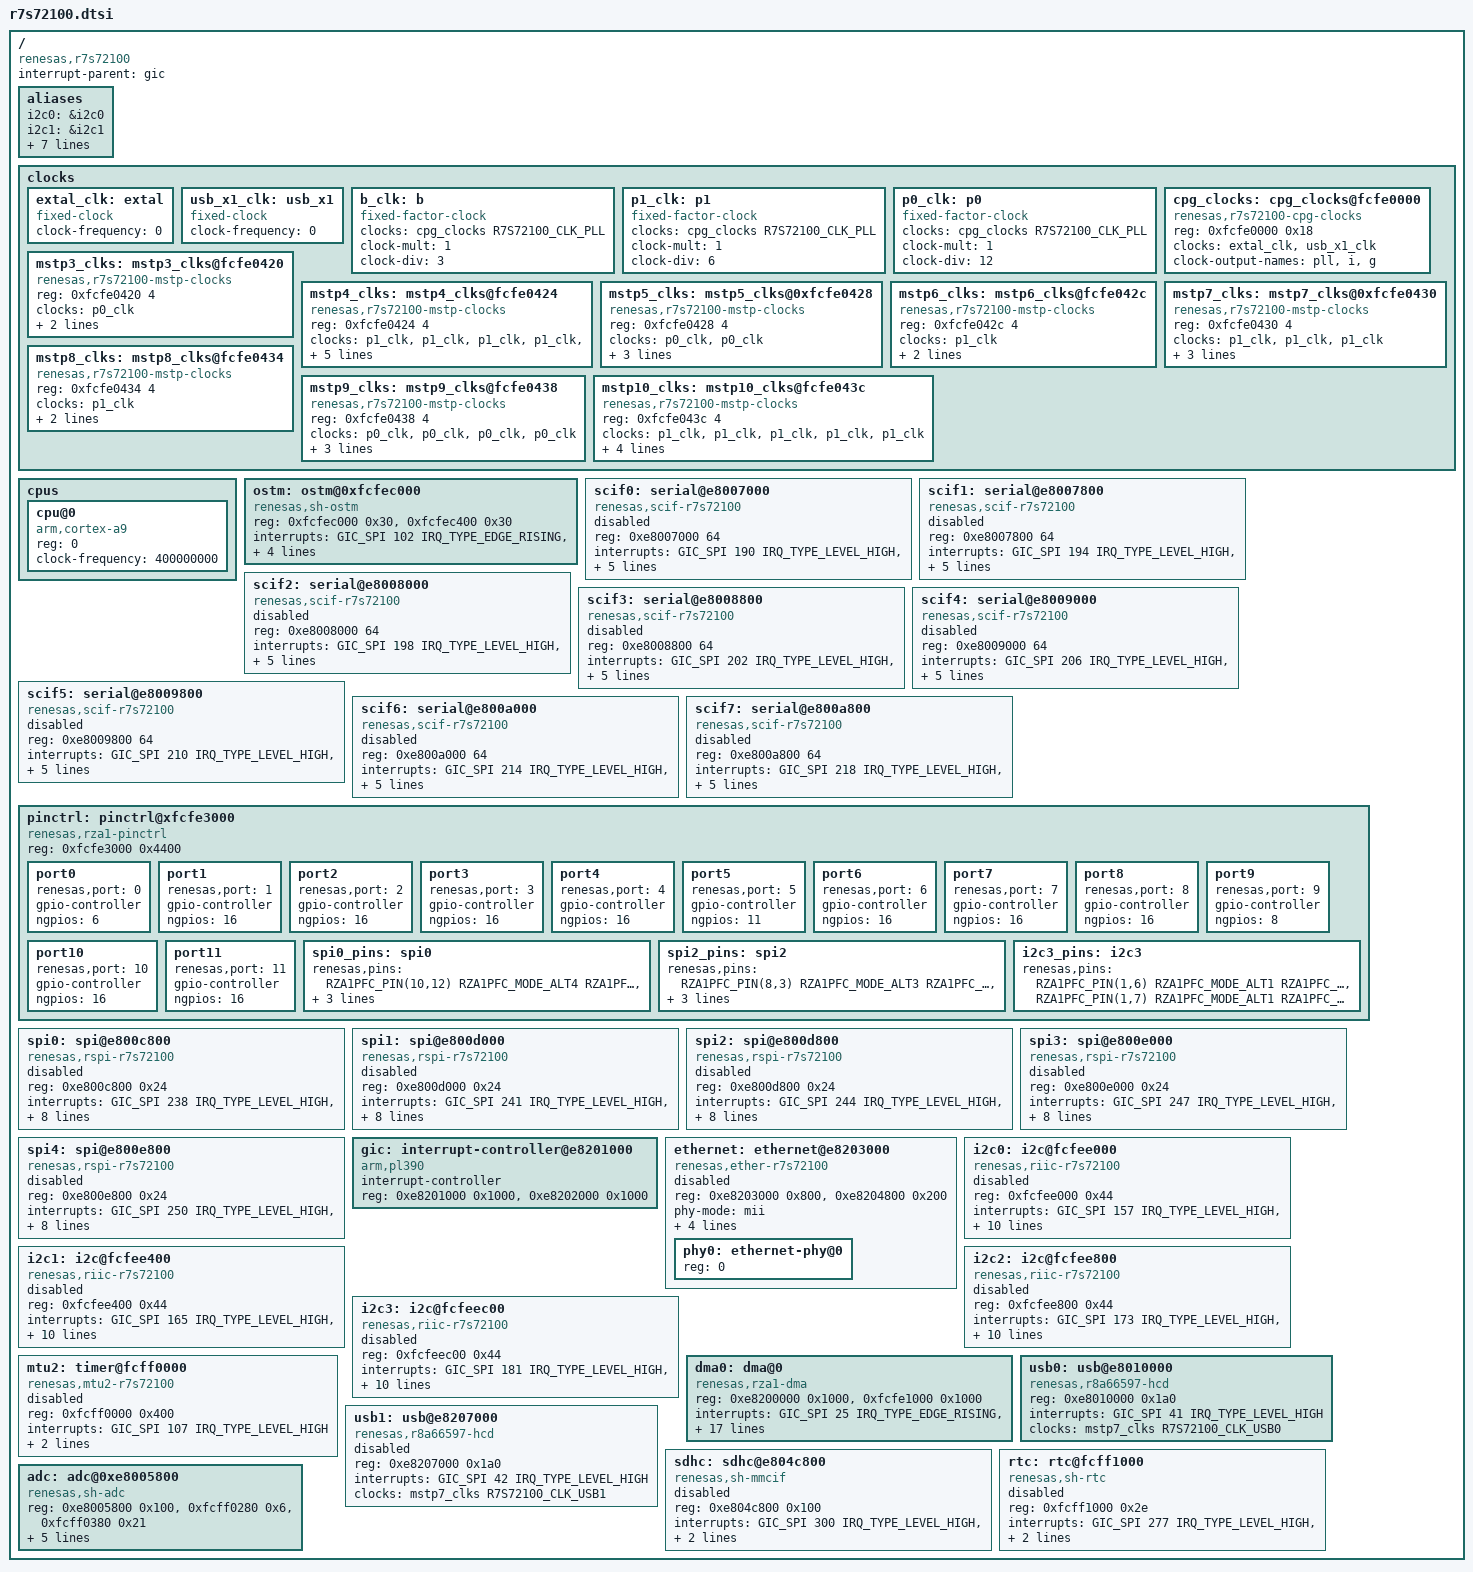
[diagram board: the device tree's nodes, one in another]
/*
 * Device Tree Source for the r7s72100 SoC
 *
 * Copyright (C) 2013-14 Renesas Solutions Corp.
 * Copyright (C) 2014 Wolfram Sang, Sang Engineering <wsa@sang-engineering.com>
 *
 * This file is licensed under the terms of the GNU General Public License
 * version 2.  This program is licensed "as is" without any warranty of any
 * kind, whether express or implied.
 */

#include <dt-bindings/pinctrl/rza1pfc.h>
#include <dt-bindings/dma/rza1dma.h>
#include <dt-bindings/clock/r7s72100-clock.h>
#include <dt-bindings/interrupt-controller/arm-gic.h>
#include <dt-bindings/interrupt-controller/irq.h>

/ {
	compatible = "renesas,r7s72100";
	interrupt-parent = <&gic>;
	#address-cells = <1>;
	#size-cells = <1>;

	aliases {
		i2c0 = &i2c0;
		i2c1 = &i2c1;
		i2c2 = &i2c2;
		i2c3 = &i2c3;
		spi0 = &spi0;
		spi1 = &spi1;
		spi2 = &spi2;
		spi3 = &spi3;
		spi4 = &spi4;
	};

	clocks {
		ranges;
		#address-cells = <1>;
		#size-cells = <1>;

		/* External clocks */
		extal_clk: extal {
			#clock-cells = <0>;
			compatible = "fixed-clock";
			/* If clk present, value must be set by board */
			clock-frequency = <0>;
		};

		usb_x1_clk: usb_x1 {
			#clock-cells = <0>;
			compatible = "fixed-clock";
			/* If clk present, value must be set by board */
			clock-frequency = <0>;
		};

		/* Fixed factor clocks */
		b_clk: b {
			#clock-cells = <0>;
			compatible = "fixed-factor-clock";
			clocks = <&cpg_clocks R7S72100_CLK_PLL>;
			clock-mult = <1>;
			clock-div = <3>;
		};
		p1_clk: p1 {
			#clock-cells = <0>;
			compatible = "fixed-factor-clock";
			clocks = <&cpg_clocks R7S72100_CLK_PLL>;
			clock-mult = <1>;
			clock-div = <6>;
		};
		p0_clk: p0 {
			#clock-cells = <0>;
			compatible = "fixed-factor-clock";
			clocks = <&cpg_clocks R7S72100_CLK_PLL>;
			clock-mult = <1>;
			clock-div = <12>;
		};

		/* Special CPG clocks */
		cpg_clocks: cpg_clocks@fcfe0000 {
			#clock-cells = <1>;
			compatible = "renesas,r7s72100-cpg-clocks",
				     "renesas,rz-cpg-clocks";
			reg = <0xfcfe0000 0x18>;
			clocks = <&extal_clk>, <&usb_x1_clk>;
			clock-output-names = "pll", "i", "g";
			#power-domain-cells = <0>;
		};

		/* MSTP clocks */
		mstp3_clks: mstp3_clks@fcfe0420 {
			#clock-cells = <1>;
			compatible = "renesas,r7s72100-mstp-clocks", "renesas,cpg-mstp-clocks";
			reg = <0xfcfe0420 4>;
			clocks = <&p0_clk>;
			clock-indices = <R7S72100_CLK_MTU2>;
			clock-output-names = "mtu2";
		};

		mstp4_clks: mstp4_clks@fcfe0424 {
			#clock-cells = <1>;
			compatible = "renesas,r7s72100-mstp-clocks", "renesas,cpg-mstp-clocks";
			reg = <0xfcfe0424 4>;
			clocks = <&p1_clk>, <&p1_clk>, <&p1_clk>, <&p1_clk>,
				 <&p1_clk>, <&p1_clk>, <&p1_clk>, <&p1_clk>;
			clock-indices = <
				R7S72100_CLK_SCIF0 R7S72100_CLK_SCIF1 R7S72100_CLK_SCIF2 R7S72100_CLK_SCIF3
				R7S72100_CLK_SCIF4 R7S72100_CLK_SCIF5 R7S72100_CLK_SCIF6 R7S72100_CLK_SCIF7
			>;
			clock-output-names = "scif0", "scif1", "scif2", "scif3", "scif4", "scif5", "scif6", "scif7";
		};
		
		mstp5_clks: mstp5_clks@0xfcfe0428 {
			#clock-cells = <1>;
			compatible = "renesas,r7s72100-mstp-clocks", "renesas,cpg-mstp-clocks";
			reg = <0xfcfe0428 4>;
			clocks = <&p0_clk>, <&p0_clk>;
			clock-indices = <
				R7S72100_CLK_OSTM1 R7S72100_CLK_OSTM0
			>;
			clock-output-names = "ostm1", "ostm0";
		};
		
		mstp6_clks: mstp6_clks@fcfe042c {
			#clock-cells = <1>;
			compatible = "renesas,r7s72100-mstp-clocks", "renesas,cpg-mstp-clocks";
			reg = <0xfcfe042c 4>;
			clocks = <&p1_clk>;
			clock-indices = <
				R7S72100_CLK_ADC
			>;
			clock-output-names = "adc";
		};
		
		mstp7_clks: mstp7_clks@0xfcfe0430 {
			#clock-cells = <1>;
			compatible = "renesas,r7s72100-mstp-clocks", "renesas,cpg-mstp-clocks";
			reg = <0xfcfe0430 4>;
			clocks = <&p1_clk>, <&p1_clk>, <&p1_clk>;
			clock-indices = <
				R7S72100_CLK_USB1 R7S72100_CLK_USB0 R7S72100_CLK_ETHER
			>;
			clock-output-names = "usb1", "usb0", "ether";
		};
		
		mstp8_clks: mstp8_clks@fcfe0434 {
			#clock-cells = <1>;
			compatible = "renesas,r7s72100-mstp-clocks", "renesas,cpg-mstp-clocks";
			reg = <0xfcfe0434 4>;
			clocks = <&p1_clk>;
			clock-indices = <
				R7S72100_CLK_MMC
			>;
			clock-output-names = "mmc";
		};

		mstp9_clks: mstp9_clks@fcfe0438 {
			#clock-cells = <1>;
			compatible = "renesas,r7s72100-mstp-clocks", "renesas,cpg-mstp-clocks";
			reg = <0xfcfe0438 4>;
			clocks = <&p0_clk>, <&p0_clk>, <&p0_clk>, <&p0_clk>;
			clock-indices = <
				R7S72100_CLK_I2C0 R7S72100_CLK_I2C1 R7S72100_CLK_I2C2 R7S72100_CLK_I2C3
			>;
			clock-output-names = "i2c0", "i2c1", "i2c2", "i2c3";
		};

		mstp10_clks: mstp10_clks@fcfe043c {
			#clock-cells = <1>;
			compatible = "renesas,r7s72100-mstp-clocks", "renesas,cpg-mstp-clocks";
			reg = <0xfcfe043c 4>;
			clocks = <&p1_clk>, <&p1_clk>, <&p1_clk>, <&p1_clk>,
				 <&p1_clk>;
			clock-indices = <
				R7S72100_CLK_SPI0 R7S72100_CLK_SPI1 R7S72100_CLK_SPI2 R7S72100_CLK_SPI3
				R7S72100_CLK_SPI4
			>;
			clock-output-names = "spi0", "spi1", "spi2", "spi3", "spi4";
		};
		
	};

	cpus {
		#address-cells = <1>;
		#size-cells = <0>;

		cpu@0 {
			device_type = "cpu";
			compatible = "arm,cortex-a9";
			reg = <0>;
			clock-frequency = <400000000>;
		};
	};
	
	ostm: ostm@0xfcfec000 {
		compatible = "renesas,sh-ostm";
		reg = <0xfcfec000 0x30>, <0xfcfec400 0x30>;
		interrupts = <GIC_SPI 102 IRQ_TYPE_EDGE_RISING>, <GIC_SPI 103 IRQ_TYPE_EDGE_RISING>;
		clocks = <&mstp5_clks R7S72100_CLK_OSTM1>, <&mstp5_clks R7S72100_CLK_OSTM0>;
		status = "okay";
		renesas,clkratings = <300 300>;
	};

	scif0: serial@e8007000 {
		compatible = "renesas,scif-r7s72100", "renesas,scif";
		reg = <0xe8007000 64>;
		interrupts = <GIC_SPI 190 IRQ_TYPE_LEVEL_HIGH>,
			     <GIC_SPI 191 IRQ_TYPE_LEVEL_HIGH>,
			     <GIC_SPI 192 IRQ_TYPE_LEVEL_HIGH>,
			     <GIC_SPI 189 IRQ_TYPE_LEVEL_HIGH>;
		clocks = <&mstp4_clks R7S72100_CLK_SCIF0>;
		clock-names = "fck";
		power-domains = <&cpg_clocks>;
		status = "disabled";
	};

	scif1: serial@e8007800 {
		compatible = "renesas,scif-r7s72100", "renesas,scif";
		reg = <0xe8007800 64>;
		interrupts = <GIC_SPI 194 IRQ_TYPE_LEVEL_HIGH>,
			     <GIC_SPI 195 IRQ_TYPE_LEVEL_HIGH>,
			     <GIC_SPI 196 IRQ_TYPE_LEVEL_HIGH>,
			     <GIC_SPI 193 IRQ_TYPE_LEVEL_HIGH>;
		clocks = <&mstp4_clks R7S72100_CLK_SCIF1>;
		clock-names = "fck";
		power-domains = <&cpg_clocks>;
		status = "disabled";
	};

	scif2: serial@e8008000 {
		compatible = "renesas,scif-r7s72100", "renesas,scif";
		reg = <0xe8008000 64>;
		interrupts = <GIC_SPI 198 IRQ_TYPE_LEVEL_HIGH>,
			     <GIC_SPI 199 IRQ_TYPE_LEVEL_HIGH>,
			     <GIC_SPI 200 IRQ_TYPE_LEVEL_HIGH>,
			     <GIC_SPI 197 IRQ_TYPE_LEVEL_HIGH>;
		clocks = <&mstp4_clks R7S72100_CLK_SCIF2>;
		clock-names = "fck";
		power-domains = <&cpg_clocks>;
		status = "disabled";
	};

	scif3: serial@e8008800 {
		compatible = "renesas,scif-r7s72100", "renesas,scif";
		reg = <0xe8008800 64>;
		interrupts = <GIC_SPI 202 IRQ_TYPE_LEVEL_HIGH>,
			     <GIC_SPI 203 IRQ_TYPE_LEVEL_HIGH>,
			     <GIC_SPI 204 IRQ_TYPE_LEVEL_HIGH>,
			     <GIC_SPI 201 IRQ_TYPE_LEVEL_HIGH>;
		clocks = <&mstp4_clks R7S72100_CLK_SCIF3>;
		clock-names = "fck";
		power-domains = <&cpg_clocks>;
		status = "disabled";
	};

	scif4: serial@e8009000 {
		compatible = "renesas,scif-r7s72100", "renesas,scif";
		reg = <0xe8009000 64>;
		interrupts = <GIC_SPI 206 IRQ_TYPE_LEVEL_HIGH>,
			     <GIC_SPI 207 IRQ_TYPE_LEVEL_HIGH>,
			     <GIC_SPI 208 IRQ_TYPE_LEVEL_HIGH>,
			     <GIC_SPI 205 IRQ_TYPE_LEVEL_HIGH>;
		clocks = <&mstp4_clks R7S72100_CLK_SCIF4>;
		clock-names = "fck";
		power-domains = <&cpg_clocks>;
		status = "disabled";
	};

	scif5: serial@e8009800 {
		compatible = "renesas,scif-r7s72100", "renesas,scif";
		reg = <0xe8009800 64>;
		interrupts = <GIC_SPI 210 IRQ_TYPE_LEVEL_HIGH>,
			     <GIC_SPI 211 IRQ_TYPE_LEVEL_HIGH>,
			     <GIC_SPI 212 IRQ_TYPE_LEVEL_HIGH>,
			     <GIC_SPI 209 IRQ_TYPE_LEVEL_HIGH>;
		clocks = <&mstp4_clks R7S72100_CLK_SCIF5>;
		clock-names = "fck";
		power-domains = <&cpg_clocks>;
		status = "disabled";
	};

	scif6: serial@e800a000 {
		compatible = "renesas,scif-r7s72100", "renesas,scif";
		reg = <0xe800a000 64>;
		interrupts = <GIC_SPI 214 IRQ_TYPE_LEVEL_HIGH>,
			     <GIC_SPI 215 IRQ_TYPE_LEVEL_HIGH>,
			     <GIC_SPI 216 IRQ_TYPE_LEVEL_HIGH>,
			     <GIC_SPI 213 IRQ_TYPE_LEVEL_HIGH>;
		clocks = <&mstp4_clks R7S72100_CLK_SCIF6>;
		clock-names = "fck";
		power-domains = <&cpg_clocks>;
		status = "disabled";
	};

	scif7: serial@e800a800 {
		compatible = "renesas,scif-r7s72100", "renesas,scif";
		reg = <0xe800a800 64>;
		interrupts = <GIC_SPI 218 IRQ_TYPE_LEVEL_HIGH>,
			     <GIC_SPI 219 IRQ_TYPE_LEVEL_HIGH>,
			     <GIC_SPI 220 IRQ_TYPE_LEVEL_HIGH>,
			     <GIC_SPI 217 IRQ_TYPE_LEVEL_HIGH>;
		clocks = <&mstp4_clks R7S72100_CLK_SCIF7>;
		clock-names = "fck";
		power-domains = <&cpg_clocks>;
		status = "disabled";
	};
	
	pinctrl: pinctrl@xfcfe3000 {
		compatible = "renesas,rza1-pinctrl";
		reg = <0xfcfe3000 0x4400>;
		
		port0: port0 {
			renesas,port = <0>;
			gpio-controller;
			#gpio-cells = <2>;
			ngpios = <6>;
		};
		
		port1: port1 {
			renesas,port = <1>;
			gpio-controller;
			#gpio-cells = <2>;
			ngpios = <16>;
		};
		
		port2: port2 {
			renesas,port = <2>;
			gpio-controller;
			#gpio-cells = <2>;
			ngpios = <16>;
		};
		
		port3: port3 {
			renesas,port = <3>;
			gpio-controller;
			#gpio-cells = <2>;
			ngpios = <16>;
		};
		
		port4: port4 {
			renesas,port = <4>;
			gpio-controller;
			#gpio-cells = <2>;
			ngpios = <16>;
		};
		
		port5: port5 {
			renesas,port = <5>;
			gpio-controller;
			#gpio-cells = <2>;
			ngpios = <11>;
		};
		
		port6: port6 {
			renesas,port = <6>;
			gpio-controller;
			#gpio-cells = <2>;
			ngpios = <16>;
		};
		
		port7: port7 {
			renesas,port = <7>;
			gpio-controller;
			#gpio-cells = <2>;
			ngpios = <16>;
		};
		
		port8: port8 {
			renesas,port = <8>;
			gpio-controller;
			#gpio-cells = <2>;
			ngpios = <16>;
		};
		
		port9: port9 {
			renesas,port = <9>;
			gpio-controller;
			#gpio-cells = <2>;
			ngpios = <8>;
		};
		
		port10: port10 {
			renesas,port = <10>;
			gpio-controller;
			#gpio-cells = <2>;
			ngpios = <16>;
		};
		
		port11: port11 {
			renesas,port = <11>;
			gpio-controller;
			#gpio-cells = <2>;
			ngpios = <16>;
		};
		
		spi0_pins: spi0 {
			renesas,pins = <RZA1PFC_PIN(10,12) RZA1PFC_MODE_ALT4 RZA1PFC_DIIO_PBDC_EN>,	/* sck */
							<RZA1PFC_PIN(10,13) RZA1PFC_MODE_ALT4 RZA1PFC_DIIO_PBDC_EN>,/* ssl */
							<RZA1PFC_PIN(10,14) RZA1PFC_MODE_ALT4 RZA1PFC_DIIO_PBDC_EN>,/* mosi */
							<RZA1PFC_PIN(10,15) RZA1PFC_MODE_ALT4 RZA1PFC_DIIO_PBDC_EN>;/* miso */
							
							
		};
		
		spi2_pins: spi2 {
			renesas,pins = <RZA1PFC_PIN(8,3) RZA1PFC_MODE_ALT3 RZA1PFC_DIIO_PBDC_EN>,	/* sck */
							<RZA1PFC_PIN(8,4) RZA1PFC_MODE_ALT3 RZA1PFC_DIIO_PBDC_EN>,	/* ssl */
							<RZA1PFC_PIN(8,5) RZA1PFC_MODE_ALT3 RZA1PFC_DIIO_PBDC_EN>,	/* mosi */
							<RZA1PFC_PIN(8,6) RZA1PFC_MODE_ALT3 RZA1PFC_DIIO_PBDC_EN>;	/* miso */
		};
								
		i2c3_pins: i2c3 {
			renesas,pins = <RZA1PFC_PIN(1,6) RZA1PFC_MODE_ALT1 RZA1PFC_DIIO_PBDC_EN>,	/* scl */
							<RZA1PFC_PIN(1,7) RZA1PFC_MODE_ALT1 RZA1PFC_DIIO_PBDC_EN>;	/* sda */
														
		};
	};
	
	spi0: spi@e800c800 {
		compatible = "renesas,rspi-r7s72100", "renesas,rspi-rz";
		reg = <0xe800c800 0x24>;
		interrupts = <GIC_SPI 238 IRQ_TYPE_LEVEL_HIGH>,
			     <GIC_SPI 239 IRQ_TYPE_LEVEL_HIGH>,
			     <GIC_SPI 240 IRQ_TYPE_LEVEL_HIGH>;
		interrupt-names = "error", "rx", "tx";
		clocks = <&mstp10_clks R7S72100_CLK_SPI0>;
		power-domains = <&cpg_clocks>;
		num-cs = <1>;
		#address-cells = <1>;
		#size-cells = <0>;
		dmas = <&dma0
					0xe800C804 
					RZA1DMA_DMARS(0x1, RZA1DMA_SPI0) 
					RZA1DMA_CHCFGM(RZA1DMA_REQD_DESTINATION, 0x0, 0x1, 0x1, RZA1DMA_AMA_BUSCYCLEMODE, RZA1DMA_CHCFG_64BIT, RZA1DMA_CHCFG_8BIT, 0x0)
					0>,
				<&dma0 
					0xe800C804 
					RZA1DMA_DMARS(0x2, RZA1DMA_SPI0)
					RZA1DMA_CHCFGM(RZA1DMA_REQD_SOURCE, 0x0, 0x1, 0x1, RZA1DMA_AMA_BUSCYCLEMODE, RZA1DMA_CHCFG_8BIT, RZA1DMA_CHCFG_8BIT, 0x0)
					0>;
		dma-names = "tx", "rx";
		status = "disabled";
	};

	spi1: spi@e800d000 {
		compatible = "renesas,rspi-r7s72100", "renesas,rspi-rz";
		reg = <0xe800d000 0x24>;
		interrupts = <GIC_SPI 241 IRQ_TYPE_LEVEL_HIGH>,
			     <GIC_SPI 242 IRQ_TYPE_LEVEL_HIGH>,
			     <GIC_SPI 243 IRQ_TYPE_LEVEL_HIGH>;
		interrupt-names = "error", "rx", "tx";
		clocks = <&mstp10_clks R7S72100_CLK_SPI1>;
		power-domains = <&cpg_clocks>;
		num-cs = <1>;
		#address-cells = <1>;
		#size-cells = <0>;
		dmas = <&dma0 
					0xe800D004 
					RZA1DMA_DMARS(0x1, RZA1DMA_SPI1) 
					RZA1DMA_CHCFGM(RZA1DMA_REQD_DESTINATION, 0x0, 0x1, 0x1, RZA1DMA_AMA_BUSCYCLEMODE, RZA1DMA_CHCFG_8BIT, RZA1DMA_CHCFG_8BIT, 0x0)
					0>,
				<&dma0 
					0xe800D004 
					RZA1DMA_DMARS(0x2, RZA1DMA_SPI1)
					RZA1DMA_CHCFGM(RZA1DMA_REQD_SOURCE, 0x0, 0x1, 0x1, RZA1DMA_AMA_BUSCYCLEMODE, RZA1DMA_CHCFG_8BIT, RZA1DMA_CHCFG_8BIT, 0x0)
					0>;
		dma-names = "tx", "rx";
		status = "disabled";
	};

	spi2: spi@e800d800 {
		compatible = "renesas,rspi-r7s72100", "renesas,rspi-rz";
		reg = <0xe800d800 0x24>;
		interrupts = <GIC_SPI 244 IRQ_TYPE_LEVEL_HIGH>,
			     <GIC_SPI 245 IRQ_TYPE_LEVEL_HIGH>,
			     <GIC_SPI 246 IRQ_TYPE_LEVEL_HIGH>;
		interrupt-names = "error", "rx", "tx";
		clocks = <&mstp10_clks R7S72100_CLK_SPI2>;
		power-domains = <&cpg_clocks>;
		num-cs = <1>;
		#address-cells = <1>;
		#size-cells = <0>;
		dmas =	<&dma0 
					0xe800D804
					RZA1DMA_DMARS(0x1, RZA1DMA_SPI2)
					RZA1DMA_CHCFGM(RZA1DMA_REQD_DESTINATION, 0x0, 0x1, 0x1, RZA1DMA_AMA_BUSCYCLEMODE, RZA1DMA_CHCFG_64BIT, RZA1DMA_CHCFG_8BIT, 0x0)
					0>,
				<&dma0
					0xe800D804 
					RZA1DMA_DMARS(0x2, RZA1DMA_SPI2)
					RZA1DMA_CHCFGM(RZA1DMA_REQD_SOURCE, 0x0, 0x1, 0x1, RZA1DMA_AMA_BUSCYCLEMODE, RZA1DMA_CHCFG_8BIT, RZA1DMA_CHCFG_8BIT, 0x0)
					0>;
		dma-names = "tx", "rx";
		status = "disabled";
	};

	spi3: spi@e800e000 {
		compatible = "renesas,rspi-r7s72100", "renesas,rspi-rz";
		reg = <0xe800e000 0x24>;
		interrupts = <GIC_SPI 247 IRQ_TYPE_LEVEL_HIGH>,
			     <GIC_SPI 248 IRQ_TYPE_LEVEL_HIGH>,
			     <GIC_SPI 249 IRQ_TYPE_LEVEL_HIGH>;
		interrupt-names = "error", "rx", "tx";
		clocks = <&mstp10_clks R7S72100_CLK_SPI3>;
		power-domains = <&cpg_clocks>;
		num-cs = <1>;
		#address-cells = <1>;
		#size-cells = <0>;
		dmas = <&dma0 
					0xe800E004
					RZA1DMA_DMARS(0x1, RZA1DMA_SPI3)
					RZA1DMA_CHCFGM(RZA1DMA_REQD_DESTINATION, 0x0, 0x1, 0x1, RZA1DMA_AMA_BUSCYCLEMODE, RZA1DMA_CHCFG_8BIT, RZA1DMA_CHCFG_8BIT, 0x0)
					0>,
				<&dma0
					0xe800E004
					RZA1DMA_DMARS(0x2, RZA1DMA_SPI3)
					RZA1DMA_CHCFGM(RZA1DMA_REQD_SOURCE, 0x0, 0x1, 0x1, RZA1DMA_AMA_BUSCYCLEMODE, RZA1DMA_CHCFG_8BIT, RZA1DMA_CHCFG_8BIT, 0x0)
					0>;
		dma-names = "tx", "rx";
		status = "disabled";
	};

	spi4: spi@e800e800 {
		compatible = "renesas,rspi-r7s72100", "renesas,rspi-rz";
		reg = <0xe800e800 0x24>;
		interrupts = <GIC_SPI 250 IRQ_TYPE_LEVEL_HIGH>,
			     <GIC_SPI 251 IRQ_TYPE_LEVEL_HIGH>,
			     <GIC_SPI 252 IRQ_TYPE_LEVEL_HIGH>;
		interrupt-names = "error", "rx", "tx";
		clocks = <&mstp10_clks R7S72100_CLK_SPI4>;
		power-domains = <&cpg_clocks>;
		num-cs = <1>;
		#address-cells = <1>;
		#size-cells = <0>;
		dmas = <&dma0 
					0xe800E804
					RZA1DMA_DMARS(0x1, RZA1DMA_SPI4)
					RZA1DMA_CHCFGM(RZA1DMA_REQD_DESTINATION, 0x0, 0x1, 0x1, RZA1DMA_AMA_BUSCYCLEMODE, RZA1DMA_CHCFG_8BIT, RZA1DMA_CHCFG_8BIT, 0x0)
					0>,
				<&dma0
					0xe800E804
					RZA1DMA_DMARS(0x2, RZA1DMA_SPI4)
					RZA1DMA_CHCFGM(RZA1DMA_REQD_SOURCE, 0x0, 0x1, 0x1, RZA1DMA_AMA_BUSCYCLEMODE, RZA1DMA_CHCFG_8BIT, RZA1DMA_CHCFG_8BIT, 0x0)
					0>;
		dma-names = "tx", "rx";
		status = "disabled";
	};

	gic: interrupt-controller@e8201000 {
		compatible = "arm,pl390";
		#interrupt-cells = <3>;
		#address-cells = <0>;
		interrupt-controller;
		reg = <0xe8201000 0x1000>,
			<0xe8202000 0x1000>;
	};

	ethernet: ethernet@e8203000 {
		compatible = "renesas,ether-r7s72100";
		reg = <0xe8203000 0x800>,
			<0xe8204800 0x200>;
		phy-mode = "mii";
		renesas,ether-link-active-low;
    	interrupts = <GIC_SPI 327 IRQ_TYPE_LEVEL_HIGH>;
    	clocks = <&mstp7_clks R7S72100_CLK_ETHER>;
    	phy-handle = <&phy0>;
    	#address-cells = <1>;
		#size-cells = <0>;
		status = "disabled";
		phy0: ethernet-phy@0 {
			reg = <0>;
		};		
	};



	i2c0: i2c@fcfee000 {
		#address-cells = <1>;
		#size-cells = <0>;
		compatible = "renesas,riic-r7s72100", "renesas,riic-rz";
		reg = <0xfcfee000 0x44>;
		interrupts = <GIC_SPI 157 IRQ_TYPE_LEVEL_HIGH>,
			     <GIC_SPI 158 IRQ_TYPE_EDGE_RISING>,
			     <GIC_SPI 159 IRQ_TYPE_EDGE_RISING>,
			     <GIC_SPI 160 IRQ_TYPE_LEVEL_HIGH>,
			     <GIC_SPI 161 IRQ_TYPE_LEVEL_HIGH>,
			     <GIC_SPI 162 IRQ_TYPE_LEVEL_HIGH>,
			     <GIC_SPI 163 IRQ_TYPE_LEVEL_HIGH>,
			     <GIC_SPI 164 IRQ_TYPE_LEVEL_HIGH>;
		clocks = <&mstp9_clks R7S72100_CLK_I2C0>;
		clock-frequency = <100000>;
		power-domains = <&cpg_clocks>;
		status = "disabled";
	};

	i2c1: i2c@fcfee400 {
		#address-cells = <1>;
		#size-cells = <0>;
		compatible = "renesas,riic-r7s72100", "renesas,riic-rz";
		reg = <0xfcfee400 0x44>;
		interrupts = <GIC_SPI 165 IRQ_TYPE_LEVEL_HIGH>,
			     <GIC_SPI 166 IRQ_TYPE_EDGE_RISING>,
			     <GIC_SPI 167 IRQ_TYPE_EDGE_RISING>,
			     <GIC_SPI 168 IRQ_TYPE_LEVEL_HIGH>,
			     <GIC_SPI 169 IRQ_TYPE_LEVEL_HIGH>,
			     <GIC_SPI 170 IRQ_TYPE_LEVEL_HIGH>,
			     <GIC_SPI 171 IRQ_TYPE_LEVEL_HIGH>,
			     <GIC_SPI 172 IRQ_TYPE_LEVEL_HIGH>;
		clocks = <&mstp9_clks R7S72100_CLK_I2C1>;
		clock-frequency = <100000>;
		power-domains = <&cpg_clocks>;
		status = "disabled";
	};

	i2c2: i2c@fcfee800 {
		#address-cells = <1>;
		#size-cells = <0>;
		compatible = "renesas,riic-r7s72100", "renesas,riic-rz";
		reg = <0xfcfee800 0x44>;
		interrupts = <GIC_SPI 173 IRQ_TYPE_LEVEL_HIGH>,
			     <GIC_SPI 174 IRQ_TYPE_EDGE_RISING>,
			     <GIC_SPI 175 IRQ_TYPE_EDGE_RISING>,
			     <GIC_SPI 176 IRQ_TYPE_LEVEL_HIGH>,
			     <GIC_SPI 177 IRQ_TYPE_LEVEL_HIGH>,
			     <GIC_SPI 178 IRQ_TYPE_LEVEL_HIGH>,
			     <GIC_SPI 179 IRQ_TYPE_LEVEL_HIGH>,
			     <GIC_SPI 180 IRQ_TYPE_LEVEL_HIGH>;
		clocks = <&mstp9_clks R7S72100_CLK_I2C2>;
		clock-frequency = <100000>;
		power-domains = <&cpg_clocks>;
		status = "disabled";
	};

	i2c3: i2c@fcfeec00 {
		#address-cells = <1>;
		#size-cells = <0>;
		compatible = "renesas,riic-r7s72100", "renesas,riic-rz";
		reg = <0xfcfeec00 0x44>;
		interrupts = <GIC_SPI 181 IRQ_TYPE_LEVEL_HIGH>,
			     <GIC_SPI 182 IRQ_TYPE_EDGE_RISING>,
			     <GIC_SPI 183 IRQ_TYPE_EDGE_RISING>,
			     <GIC_SPI 184 IRQ_TYPE_LEVEL_HIGH>,
			     <GIC_SPI 185 IRQ_TYPE_LEVEL_HIGH>,
			     <GIC_SPI 186 IRQ_TYPE_LEVEL_HIGH>,
			     <GIC_SPI 187 IRQ_TYPE_LEVEL_HIGH>,
			     <GIC_SPI 188 IRQ_TYPE_LEVEL_HIGH>;
		clocks = <&mstp9_clks R7S72100_CLK_I2C3>;
		clock-frequency = <100000>;
		power-domains = <&cpg_clocks>;
		status = "disabled";
	};

	mtu2: timer@fcff0000 {
		compatible = "renesas,mtu2-r7s72100", "renesas,mtu2";
		reg = <0xfcff0000 0x400>;
		interrupts = <GIC_SPI 107 IRQ_TYPE_LEVEL_HIGH>;
		interrupt-names = "tgi0a";
		clocks = <&mstp3_clks R7S72100_CLK_MTU2>;
		clock-names = "fck";
		power-domains = <&cpg_clocks>;
		status = "disabled";
	};
	
	dma0: dma@0 {
		compatible = "renesas,rza1-dma";
		reg = <0xe8200000 0x1000>,
		 <0xfcfe1000 0x1000>;
		 interrupts =
		 		<GIC_SPI 25 IRQ_TYPE_EDGE_RISING>,	/* error */
		 		<GIC_SPI 9 IRQ_TYPE_EDGE_RISING>,	/* chan0 */
		 		<GIC_SPI 10 IRQ_TYPE_EDGE_RISING>,	/* chan1 */
				<GIC_SPI 11 IRQ_TYPE_EDGE_RISING>,	/* chan2 */
				<GIC_SPI 12 IRQ_TYPE_EDGE_RISING>,	/* chan3 */
				<GIC_SPI 13 IRQ_TYPE_EDGE_RISING>,	/* chan4 */
				<GIC_SPI 14 IRQ_TYPE_EDGE_RISING>,	/* chan5 */
				<GIC_SPI 15 IRQ_TYPE_EDGE_RISING>,	/* chan6 */
				<GIC_SPI 16 IRQ_TYPE_EDGE_RISING>,	/* chan7 */
				<GIC_SPI 17 IRQ_TYPE_EDGE_RISING>,	/* chan8 */
				<GIC_SPI 18 IRQ_TYPE_EDGE_RISING>,	/* chan9 */
				<GIC_SPI 19 IRQ_TYPE_EDGE_RISING>,	/* chan10 */
				<GIC_SPI 20 IRQ_TYPE_EDGE_RISING>,	/* chan11 */
				<GIC_SPI 21 IRQ_TYPE_EDGE_RISING>,	/* chan12 */
				<GIC_SPI 22 IRQ_TYPE_EDGE_RISING>,	/* chan13 */
				<GIC_SPI 23 IRQ_TYPE_EDGE_RISING>,	/* chan14 */
				<GIC_SPI 24 IRQ_TYPE_EDGE_RISING>;	/* chan15 */	
		#dma-cells = <4>; /* registeraddr, dmars, chcfg, interval */
		dma-channels = <16>; /* this can be set to the actual amount of interrupts used to save memory */
	};

	usb0: usb@e8010000 {
		compatible = "renesas,r8a66597-hcd";
		reg = <0xe8010000 0x1a0>;
		interrupts = <GIC_SPI 41 IRQ_TYPE_LEVEL_HIGH>;
		clocks = <&mstp7_clks R7S72100_CLK_USB0>;
		clock-names = "clk";
	};
	
	usb1: usb@e8207000 {
		compatible = "renesas,r8a66597-hcd";
		reg = <0xe8207000 0x1a0>;
		interrupts = <GIC_SPI 42 IRQ_TYPE_LEVEL_HIGH>;
		clocks = <&mstp7_clks R7S72100_CLK_USB1>;
		clock-names = "usb-1";
		status = "disabled";
	};
			
	sdhc: sdhc@e804c800 {
		compatible = "renesas,sh-mmcif";
		reg = <0xe804c800 0x100>;
		interrupts = <GIC_SPI 300 IRQ_TYPE_LEVEL_HIGH>,
		<GIC_SPI 301 IRQ_TYPE_LEVEL_HIGH>;
		clocks = <&mstp8_clks R7S72100_CLK_MMC>;
		status = "disabled";
	};
	
	rtc: rtc@fcff1000 {
		compatible = "renesas,sh-rtc";
		reg = <0xfcff1000 0x2e>;
		interrupts = <GIC_SPI 277 IRQ_TYPE_LEVEL_HIGH>,
			<GIC_SPI 278 IRQ_TYPE_LEVEL_HIGH>,
			<GIC_SPI 276 IRQ_TYPE_LEVEL_HIGH>;
		status = "disabled";
	};
	
	adc: adc@0xe8005800 {
		compatible = "renesas,sh-adc";
		reg = <0xe8005800 0x100>,
			<0xfcff0280 0x6>,
			<0xfcff0380 0x21>;
		interrupts = <GIC_SPI 138 IRQ_TYPE_LEVEL_HIGH>,
			<GIC_SPI 139 IRQ_TYPE_LEVEL_HIGH>,
			<GIC_SPI 114 IRQ_TYPE_LEVEL_HIGH>;
		clocks = <&mstp6_clks R7S72100_CLK_ADC>, 
			<&mstp3_clks R7S72100_CLK_MTU2>;
		clock-names = "mtu2_fck", "adc0";
	};
};
